# HR_C7000_DM32 register map
Vendor: Dahua Technology (chip); Baofeng (radio product); Series: HR_C7000; File version: 0.1-dm32re-draft
CPU: other r0p0, little endian, no MPU, no FPU, 0 interrupt priority bits
Registers are 32-bit, read-write, reset 0x0 unless marked. A register's access mark holds for its fields unless they carry their own. Offsets are from the block's base; [hi:lo] are bit positions; lines under a group give offsets from that group; {n}, {i} and the like mark numbered series.

## TIMER — DesignWare APB timer (dw_apb_timer), 6 channels of 32-bit down-counters at a 0x14 stride (DS §4.8, p.187-200; Register Table 6 p.188-189). Checked against a live register read of a running DM-32UV (2026-09-27/28). Datasheet errors: Register Table 6 prints Timer5 and Timer6 at 0x3c-0x4c (a copy of Timer4's rows) and §4.8.5.21-30 at 0x0-0x10 (a copy of Timer1's); the stride puts them at 0x50 and 0x64, where the live read shows Timer6 running and where the firmware accesses them (+0x50..+0x70). Datasheet field names are TimerEnable / TimerMode / TimerInterruptMask; this block uses enable / mode / int_mask. TIMERS_COMP_VERSION reads 0x3230322a (DS p.200 and the live read). Channel 0 (TIMER_1) is the uC/OS-III tick: on a live radio LoadCount = 0xcd140, ControlReg = 0x03 (enabled, periodic, unmasked). It is PIC source 1, CPU vector 33 (DS Table 30). Confirmed on hardware 2026-10-01: with source 33 unmasked instead, the timer counted and held its line but nothing was delivered; with source 1 unmasked the ISR fired. Channel 5 (TIMER_6, source 6) drives the 10 Hz UI tick. Not the layout of QEMU's stock csky_timer device, which lacks the per-channel EOI/IntStatus registers (QEMU: dm32uv-qemu hw/timer/dm32_timer.c).
Base 0x14000000
{0x0+0x14*i} TIMER_CH[{i}] (i=0..5) group — Per-channel timer registers, 0x14-byte stride, 6 instances (Timer1..Timer6)
  0x00 LoadCount — Reload value loaded into CurrentValue on enable/underflow
  0x04 CurrentValue ro — Live down-counter, counts down from LoadCount
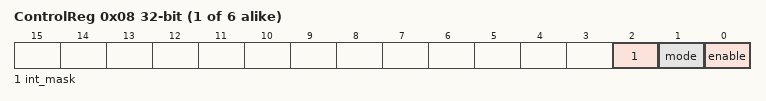
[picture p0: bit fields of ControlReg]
  0x08 ControlReg — Timer channel control
    [2] int_mask — 1=this channel's interrupt is masked
    [1] mode — 1=user/periodic mode
    [0] enable — Timer channel enable
  0x0C EOI ro — Read to clear this channel's interrupt (end-of-interrupt)
  0x10 IntStatus ro — This channel's masked interrupt status
0xA0 TimersIntStatus ro — All-channel masked interrupt status
0xA4 TimersEOI ro — Read to clear all channels' interrupts
0xA8 TimersRawIntStatus ro — All-channel unmasked (raw) interrupt status
0xAC TIMERS_COMP_VERSION ro — DesignWare IP component version register

## i8080 — i8080-style parallel LCD bus controller (DS §5.3, p.264-268). Drives the DM-32's ST7789V-class panel controller (identified 2026-10-11 from the stock init sequence, which uses ST7789V-only commands B2/B7/BB/C0/C2/C3/C6/D0; earlier notes said HX8353E, which rested only on shared MIPI DCS commands): INDEX (+0x0) carries panel commands and DATA (+0x4) pixel/parameter data. FW: 5 direct access sites (init in the LCD driver) plus base literals at 0x0303dad0, 0x0304242c.
Base 0x12000000
0x00 INDEX — Addressing register. DS §5.3.5.1 p.266. FW: 0 reads, 1 write. Reset 0x0 (DS).
  [31:0] INDEX0 — Port Index Register [reset 0x0] [access RW]
0x04 DATA — Data register. DS §5.3.5.2 p.266. FW: 0 reads, 1 write. Reset 0x0 (DS).
  [31:0] DATA0 — Port data register [reset 0x0] [access RW]
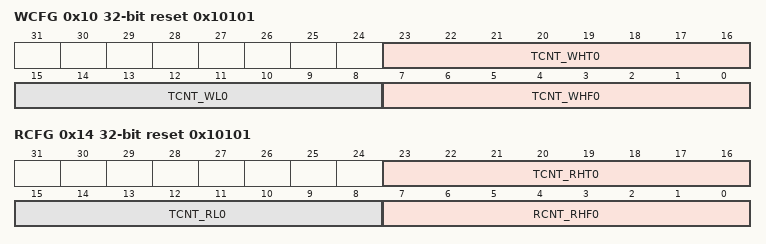
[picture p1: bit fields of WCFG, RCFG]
0x10 WCFG reset 0x10101 — Write timing parameter configuration. DS §5.3.5.3 p.266. FW: 0 reads, 1 write. Reset 0x10101 (DS).
  [23:16] TCNT_WHT0 — Write strobe tail invalid cycle [reset 0x1] [access RW]
  [15:8] TCNT_WL0 — Write strobe valid period [reset 0x1] [access RW]
  [7:0] TCNT_WHF0 — Write strobe header invalidation cycle [reset 0x1] [access RW]
0x14 RCFG reset 0x10101 — Read timing parameter configuration. DS §5.3.5.4 p.266. The datasheet prints the reserved row as [31:0], overlapping the fields; reserved is [31:24] by analogy with WCFG. Reset 0x10101 (DS).
  [23:16] TCNT_RHT0 — Read strobe tail inactive cycles (port 0) [reset 0x1] [access RW]
  [15:8] TCNT_RL0 — Read strobe active period (port 0) [reset 0x1] [access RW]
  [7:0] RCNT_RHF0 — Read strobe head inactive cycles (port 0). Printed RCNT_RHF0; by symmetry with TCNT_WHF0 probably TCNT_RHF0 [reset 0x1] [access RW]
0x20 SCFG — Configuration registers. DS §5.3.5.5 p.268. Reset 0x0 (DS).
  [31:0] P0_SCFG — Port Configuration Register [reset 0x0] [access RW]
0x28 UNDOC_0x28 — Not in the datasheet's I80 register table. The stock firmware reads and writes it (FW: 1 read, 1 write). Role unknown.
0x2C AC_MODE — Bus Mode Register. DS §5.3.5.6 p.268. Reset 0x0 (DS).
  [31:0] BUSHS — Bus Mode Control Register [reset 0x0] [access RW]
